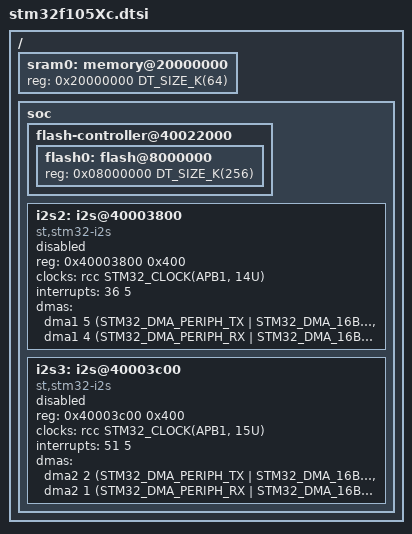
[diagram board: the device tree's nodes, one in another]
/*
 * Copyright (c) 2019 Argentum Systems Ltd.
 *
 * SPDX-License-Identifier: Apache-2.0
 */

#include <mem.h>
#include <st/f1/stm32f105.dtsi>

/ {
	sram0: memory@20000000 {
		reg = <0x20000000 DT_SIZE_K(64)>;
	};

	soc {
		flash-controller@40022000 {
			flash0: flash@8000000 {
				reg = <0x08000000 DT_SIZE_K(256)>;
			};
		};

		i2s2: i2s@40003800 {
			compatible = "st,stm32-i2s";
			#address-cells = <1>;
			#size-cells = <0>;
			reg = <0x40003800 0x400>;
			clocks = <&rcc STM32_CLOCK(APB1, 14U)>;
			interrupts = <36 5>;
			dmas = <&dma1 5 (STM32_DMA_PERIPH_TX | STM32_DMA_16BITS | STM32_DMA_PRIORITY_HIGH)
				&dma1 4 (STM32_DMA_PERIPH_RX | STM32_DMA_16BITS | STM32_DMA_PRIORITY_HIGH)>;
			dma-names = "tx", "rx";
			status = "disabled";
		};

		i2s3: i2s@40003c00 {
			compatible = "st,stm32-i2s";
			#address-cells = <1>;
			#size-cells = <0>;
			reg = <0x40003c00 0x400>;
			clocks = <&rcc STM32_CLOCK(APB1, 15U)>;
			interrupts = <51 5>;
			dmas = <&dma2 2 (STM32_DMA_PERIPH_TX | STM32_DMA_16BITS | STM32_DMA_PRIORITY_HIGH)
				&dma2 1 (STM32_DMA_PERIPH_RX | STM32_DMA_16BITS | STM32_DMA_PRIORITY_HIGH)>;
			dma-names = "tx", "rx";
			status = "disabled";
		};
	};
};
